# f28p65x_de_regs register map
Vendor: Texas Instruments
Peripheral module from a debugger description file (folder C2000).
Address unit: 16 bits
Registers are 32-bit, read-write, no defined reset value unless marked. A register's access mark holds for its fields unless they carry their own. Offsets are as the file gives them; lines under a group give offsets from that group; [hi:lo] are bit positions; {n}, {i} and the like mark numbered series; 'fields as' and 'values as' point back to an identical list; <NAME> marks a mode.

## DE_REGS — DE Registers
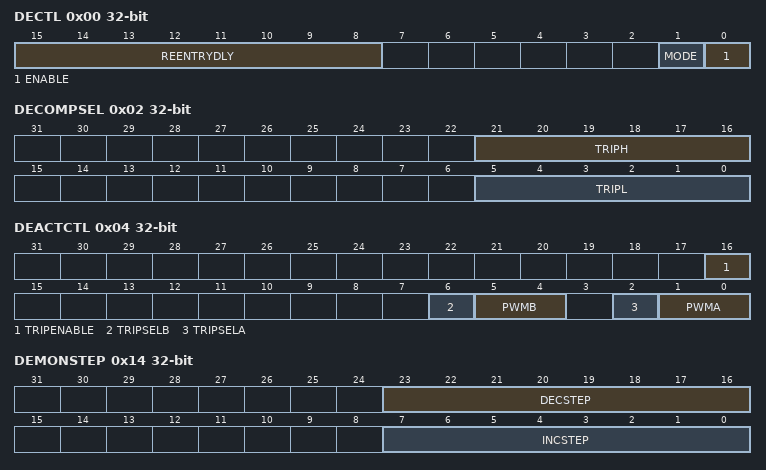
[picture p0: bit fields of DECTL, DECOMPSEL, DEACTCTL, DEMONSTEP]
0x00 DECTL — DE control register
  [15:8] REENTRYDLY — Re-entry delay value
  [1] MODE — DE Mode
  [0] ENABLE — DE function enable.
0x02 DECOMPSEL — DE comparator source select register
  [21:16] TRIPH — Comparator TRIPH source select.
  [5:0] TRIPL — Comparator TRIPL source select.
0x04 DEACTCTL — DE Action Control
  [16] TRIPENABLE — Enables PWMTRIP condition to bypassDiode emulation logic.
  [6] TRIPSELB — Trip source select on PWMB output
  [5:4] PWMB — Comparator source select.
  [2] TRIPSELA — Trip source select on PWMA output
  [1:0] PWMA — Comparator source select.
0x06 DESTS ro — DE Status register
  [0] DEACTIVE — Diode Emulation mode active flag.
0x08 DEFRC — DE Status force register
  [0] DEACTIVE — Diode Emulation mode active flag force.
0x0A DECLR — DE Status clear register
  [0] DEACTIVE — Diode Emulation mode active flag clear.
0x10 DEMONCNT ro — DE trip monitor counter
  [15:0] CNT — DEACTIVE monitor counter
0x12 DEMONCTL — DE monitor mode control
  [0] ENABLE — DEACTIVE monitor counter
0x14 DEMONSTEP — DE monitor counter step
  [23:16] DECSTEP — DE monitor counter decrement step.
  [7:0] INCSTEP — DE monitor counter increment step.
0x16 DEMONTHRES — DE monitor counter threshold
  [15:0] THRESHOLD — DE monitor counter compare threshold.
